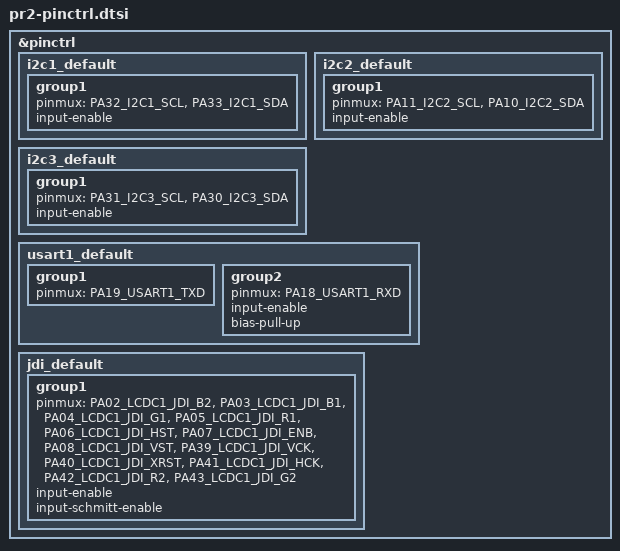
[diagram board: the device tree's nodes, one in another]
/*
 * Copyright (c) 2026 Core Devices LLC
 * SPDX-License-Identifier: Apache-2.0
 */

#include <zephyr/dt-bindings/pinctrl/sf32lb52x-pinctrl.h>

&pinctrl {
	i2c1_default: i2c1_default {
		group1 {
			pinmux = <PA32_I2C1_SCL>, <PA33_I2C1_SDA>;
			input-enable;
		};
	};

	i2c2_default: i2c2_default {
		group1 {
			pinmux = <PA11_I2C2_SCL>, <PA10_I2C2_SDA>;
			input-enable;
		};
	};

	i2c3_default: i2c3_default {
		group1 {
			pinmux = <PA31_I2C3_SCL>, <PA30_I2C3_SDA>;
			input-enable;
		};
	};

	usart1_default: usart1_default {
		group1 {
			pinmux = <PA19_USART1_TXD>;
		};

		group2 {
			pinmux = <PA18_USART1_RXD>;
			input-enable;
			bias-pull-up;
		};
	};

	jdi_default: jdi_default {
		group1 {
			pinmux = <PA02_LCDC1_JDI_B2>,
				 <PA03_LCDC1_JDI_B1>,
				 <PA04_LCDC1_JDI_G1>,
				 <PA05_LCDC1_JDI_R1>,
				 <PA06_LCDC1_JDI_HST>,
				 <PA07_LCDC1_JDI_ENB>,
				 <PA08_LCDC1_JDI_VST>,
				 <PA39_LCDC1_JDI_VCK>,
				 <PA40_LCDC1_JDI_XRST>,
				 <PA41_LCDC1_JDI_HCK>,
				 <PA42_LCDC1_JDI_R2>,
				 <PA43_LCDC1_JDI_G2>;
			input-enable;
			input-schmitt-enable;
		};
	};
};
